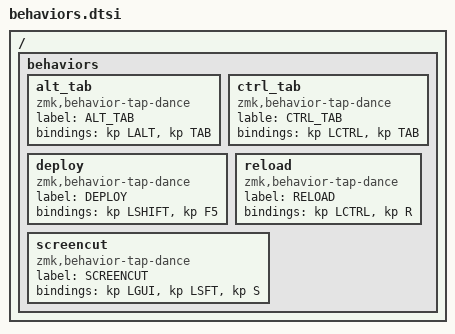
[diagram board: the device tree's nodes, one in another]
/ {
    behaviors {
        alt_tab: alt_tab {
            compatible = "zmk,behavior-tap-dance";
            label = "ALT_TAB";
            bindings = <&kp LALT &kp TAB>;
        };

        ctrl_tab: ctrl_tab {
            compatible = "zmk,behavior-tap-dance";
            lable = "CTRL_TAB";
            bindings = <&kp LCTRL &kp TAB>;
        };

        deploy: deploy {
            compatible = "zmk,behavior-tap-dance";
            label = "DEPLOY";
            bindings = <&kp LSHIFT &kp F5>;
        };

        reload: reload {
            compatible = "zmk,behavior-tap-dance";
            label = "RELOAD";
            bindings = <&kp LCTRL &kp R>;
        };

         screencut: screencut {
            compatible = "zmk,behavior-tap-dance";
            label = "SCREENCUT";
            bindings = <&kp LGUI &kp LSFT &kp S>;
        };
    };
};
